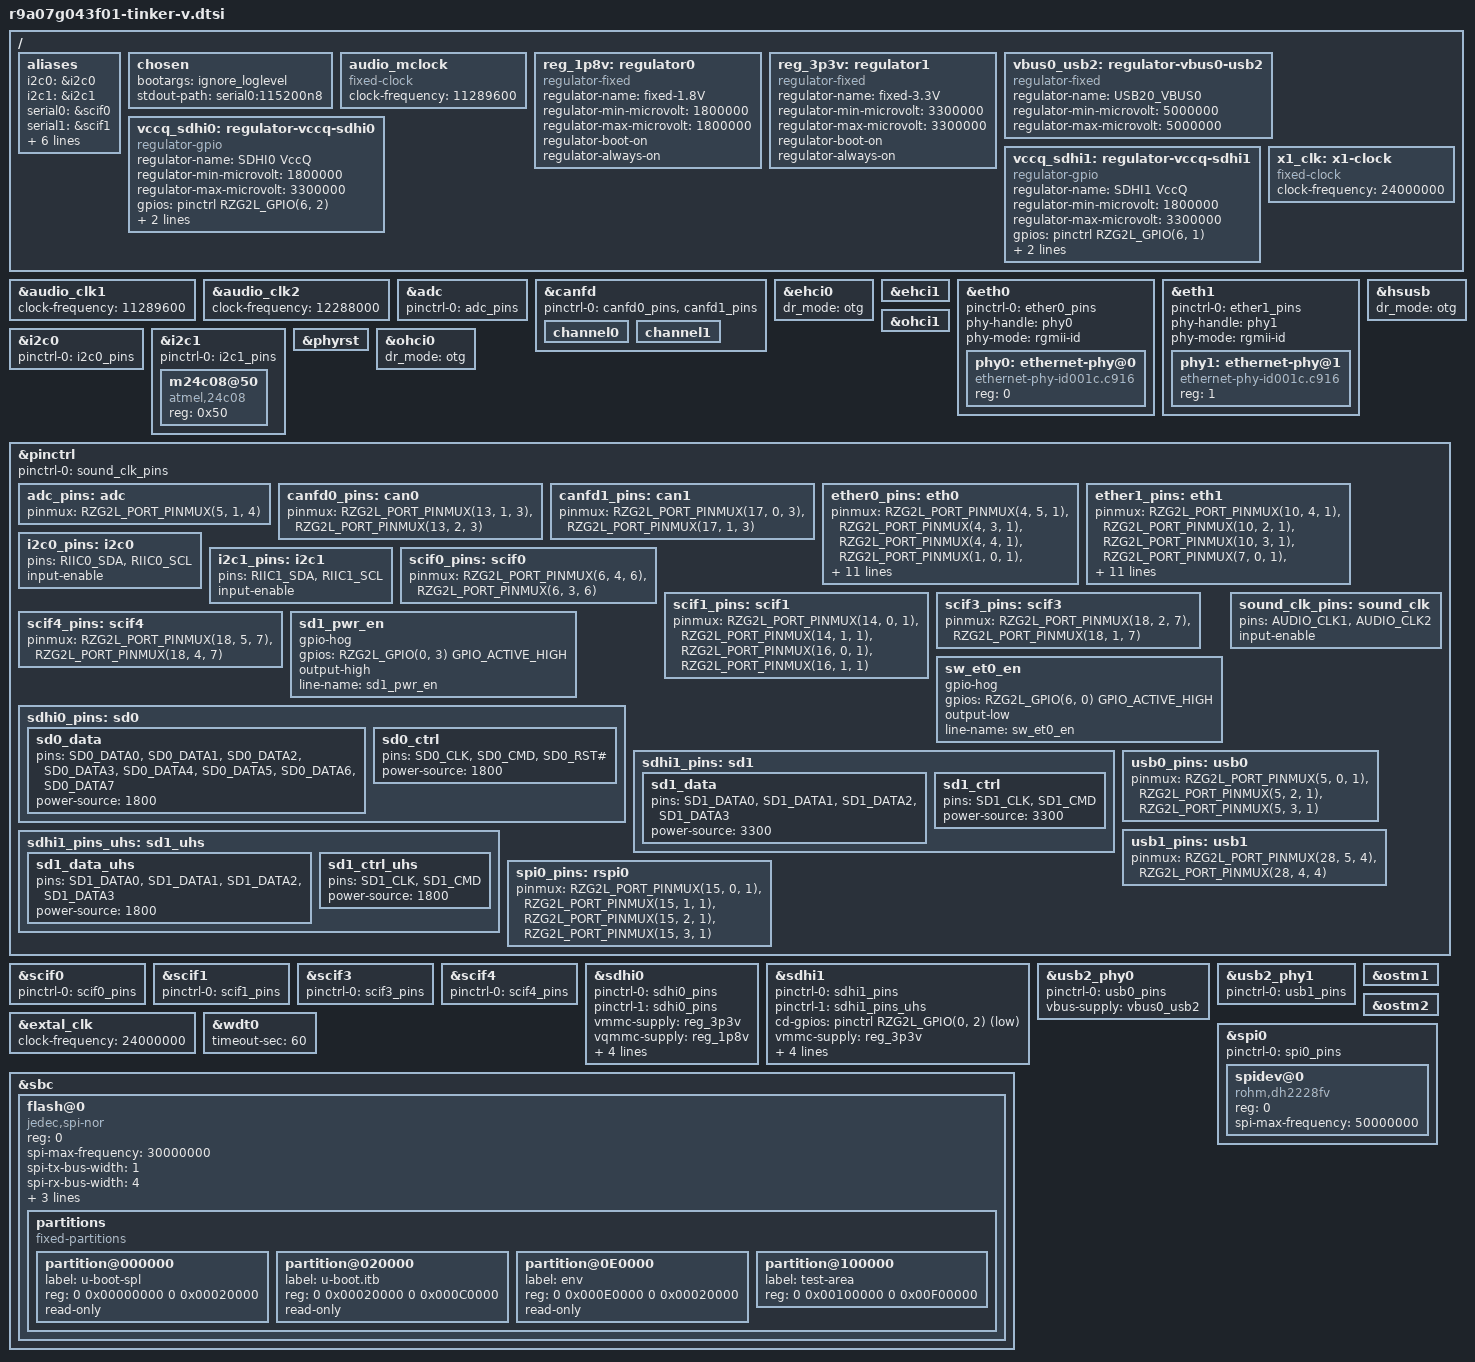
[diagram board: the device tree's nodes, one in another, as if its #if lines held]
// SPDX-License-Identifier: GPL-2.0
/*
 * Device Tree Source for the RZ/Five Evaluation Board Kit
 *
 * Copyright (C) 2022 Renesas Electronics Corp.
 */

#include <dt-bindings/pinctrl/rzg2l-pinctrl.h>
#include <dt-bindings/gpio/gpio.h>

/ {
	aliases {
		i2c0 = &i2c0;
		i2c1 = &i2c1;
		serial0 = &scif0;
		serial1 = &scif1;
		serial3 = &scif3;
		serial4 = &scif4;
		mmc0 = &sdhi0;
		mmc1 = &sdhi1;
		ethernet0 = &eth0;
		ethernet1 = &eth1;
	};

	chosen {
		bootargs = "ignore_loglevel";
		stdout-path = "serial0:115200n8";
	};

	audio_mclock: audio_mclock {
		compatible = "fixed-clock";
		#clock-cells = <0>;
		clock-frequency = <11289600>;
	};

	reg_1p8v: regulator0 {
		compatible = "regulator-fixed";

		regulator-name = "fixed-1.8V";
		regulator-min-microvolt = <1800000>;
		regulator-max-microvolt = <1800000>;
		regulator-boot-on;
		regulator-always-on;
	};

	reg_3p3v: regulator1 {
		compatible = "regulator-fixed";

		regulator-name = "fixed-3.3V";
		regulator-min-microvolt = <3300000>;
		regulator-max-microvolt = <3300000>;
		regulator-boot-on;
		regulator-always-on;
	};

	vbus0_usb2: regulator-vbus0-usb2 {
		compatible = "regulator-fixed";

		regulator-name = "USB20_VBUS0";
		regulator-min-microvolt = <5000000>;
		regulator-max-microvolt = <5000000>;
	};

#if !(SW_SW0_DEV_SEL)
	vccq_sdhi0: regulator-vccq-sdhi0 {
		compatible = "regulator-gpio";

		regulator-name = "SDHI0 VccQ";
		regulator-min-microvolt = <1800000>;
		regulator-max-microvolt = <3300000>;

		gpios = <&pinctrl RZG2L_GPIO(6, 2) GPIO_ACTIVE_HIGH>;

		gpios-states = <1>;
		states = <3300000 1
			  1800000 0>;
	};
#endif

	vccq_sdhi1: regulator-vccq-sdhi1 {
		compatible = "regulator-gpio";

		regulator-name = "SDHI1 VccQ";
		regulator-min-microvolt = <1800000>;
		regulator-max-microvolt = <3300000>;

		gpios = <&pinctrl RZG2L_GPIO(6, 1) GPIO_ACTIVE_HIGH>;

		gpios-states = <1>;
		states = <3300000 1
			  1800000 0>;
	};

	x1_clk: x1-clock {
		compatible = "fixed-clock";
		#clock-cells = <0>;
		clock-frequency = <24000000>;
	};
};

&audio_clk1{
	clock-frequency = <11289600>;
};

&audio_clk2{
	clock-frequency = <12288000>;
};

&adc {
	pinctrl-0 = <&adc_pins>;
	pinctrl-names = "default";
	status = "okay";
};

&canfd {
	pinctrl-0 = <&canfd0_pins &canfd1_pins>;
	pinctrl-names = "default";
	status = "okay";
	channel0 {
		status = "okay";
	};
	channel1 {
		status = "okay";
	};
};

&ehci0 {
	dr_mode = "otg";
	status = "okay";
};

&ehci1 {
	status = "okay";
};

&eth0 {
	pinctrl-0 = <&ether0_pins>;
	pinctrl-names = "default";
	phy-handle = <&phy0>;
	phy-mode = "rgmii-id";
	status = "okay";

	phy0: ethernet-phy@0 {
		compatible = "ethernet-phy-id001c.c916",
			     "ethernet-phy-ieee802.3-c22";
		reg = <0>;
	};
};

&eth1 {
	pinctrl-0 = <&ether1_pins>;
	pinctrl-names = "default";
	phy-handle = <&phy1>;
	phy-mode = "rgmii-id";
	status = "okay";

	phy1: ethernet-phy@1 {
		compatible = "ethernet-phy-id001c.c916",
			     "ethernet-phy-ieee802.3-c22";
		reg = <1>;
	};
};

&hsusb {
	dr_mode = "otg";
	status = "okay";
};

&i2c0 {
	pinctrl-0 = <&i2c0_pins>;
	pinctrl-names = "default";

	status = "okay";
};

&i2c1 {
	pinctrl-0 = <&i2c1_pins>;
	pinctrl-names = "default";
	status = "okay";

	m24c08@50 {
		compatible = "atmel,24c08";
		reg = <0x50>;
		status = "okay";
	};
};

&phyrst {
	status = "okay";
};

&ohci0 {
	dr_mode = "otg";
	status = "okay";
};

&ohci1 {
	status = "okay";
};

&pinctrl {
	pinctrl-0 = <&sound_clk_pins>;
	pinctrl-names = "default";

	adc_pins: adc {
		pinmux = <RZG2L_PORT_PINMUX(5, 1, 4)>; /* ADC_TRG */
	};

	canfd0_pins: can0 {
		pinmux = <RZG2L_PORT_PINMUX(13, 1, 3)>, /* TX */
			 <RZG2L_PORT_PINMUX(13, 2, 3)>; /* RX */
	};

	canfd1_pins: can1 {
		pinmux = <RZG2L_PORT_PINMUX(17, 0, 3)>, /* TX */
			 <RZG2L_PORT_PINMUX(17, 1, 3)>; /* RX */
	};

	ether0_pins: eth0 {
		pinmux = <RZG2L_PORT_PINMUX(4, 5, 1)>, /* ET0_LINKSTA */
			 <RZG2L_PORT_PINMUX(4, 3, 1)>, /* ET0_MDC */
			 <RZG2L_PORT_PINMUX(4, 4, 1)>, /* ET0_MDIO */
			 <RZG2L_PORT_PINMUX(1, 0, 1)>, /* ET0_TXC */
			 <RZG2L_PORT_PINMUX(1, 1, 1)>, /* ET0_TX_CTL */
			 <RZG2L_PORT_PINMUX(1, 2, 1)>, /* ET0_TXD0 */
			 <RZG2L_PORT_PINMUX(1, 3, 1)>, /* ET0_TXD1 */
			 <RZG2L_PORT_PINMUX(1, 4, 1)>, /* ET0_TXD2 */
			 <RZG2L_PORT_PINMUX(2, 0, 1)>, /* ET0_TXD3 */
			 <RZG2L_PORT_PINMUX(3, 0, 1)>, /* ET0_RXC */
			 <RZG2L_PORT_PINMUX(3, 1, 1)>, /* ET0_RX_CTL */
			 <RZG2L_PORT_PINMUX(3, 2, 1)>, /* ET0_RXD0 */
			 <RZG2L_PORT_PINMUX(3, 3, 1)>, /* ET0_RXD1 */
			 <RZG2L_PORT_PINMUX(4, 0, 1)>, /* ET0_RXD2 */
			 <RZG2L_PORT_PINMUX(4, 1, 1)>; /* ET0_RXD3 */
	};

	ether1_pins: eth1 {
		pinmux = <RZG2L_PORT_PINMUX(10, 4, 1)>, /* ET1_LINKSTA */
			 <RZG2L_PORT_PINMUX(10, 2, 1)>, /* ET1_MDC */
			 <RZG2L_PORT_PINMUX(10, 3, 1)>, /* ET1_MDIO */
			 <RZG2L_PORT_PINMUX(7, 0, 1)>, /* ET1_TXC */
			 <RZG2L_PORT_PINMUX(7, 1, 1)>, /* ET1_TX_CTL */
			 <RZG2L_PORT_PINMUX(7, 2, 1)>, /* ET1_TXD0 */
			 <RZG2L_PORT_PINMUX(7, 3, 1)>, /* ET1_TXD1 */
			 <RZG2L_PORT_PINMUX(7, 4, 1)>, /* ET1_TXD2 */
			 <RZG2L_PORT_PINMUX(8, 0, 1)>, /* ET1_TXD3 */
			 <RZG2L_PORT_PINMUX(8, 4, 1)>, /* ET1_RXC */
			 <RZG2L_PORT_PINMUX(9, 0, 1)>, /* ET1_RX_CTL */
			 <RZG2L_PORT_PINMUX(9, 1, 1)>, /* ET1_RXD0 */
			 <RZG2L_PORT_PINMUX(9, 2, 1)>, /* ET1_RXD1 */
			 <RZG2L_PORT_PINMUX(9, 3, 1)>, /* ET1_RXD2 */
			 <RZG2L_PORT_PINMUX(10, 0, 1)>; /* ET1_RXD3 */
	};

	i2c0_pins: i2c0 {
		pins = "RIIC0_SDA", "RIIC0_SCL";
		input-enable;
	};

	i2c1_pins: i2c1 {
		pins = "RIIC1_SDA", "RIIC1_SCL";
		input-enable;
	};

	scif0_pins: scif0 {
		pinmux = <RZG2L_PORT_PINMUX(6, 4, 6)>, /* TX */
			 <RZG2L_PORT_PINMUX(6, 3, 6)>; /* RX */
	};

	scif1_pins: scif1 {
		pinmux = <RZG2L_PORT_PINMUX(14, 0, 1)>, /* TX */
			 <RZG2L_PORT_PINMUX(14, 1, 1)>, /* RX */
			 <RZG2L_PORT_PINMUX(16, 0, 1)>, /* CTS */
			 <RZG2L_PORT_PINMUX(16, 1, 1)>; /* RTS */
	};

	scif3_pins: scif3 {
		pinmux = <RZG2L_PORT_PINMUX(18, 2, 7)>, /* TX */
			 <RZG2L_PORT_PINMUX(18, 1, 7)>; /* RX */
	};

	scif4_pins: scif4 {
		pinmux = <RZG2L_PORT_PINMUX(18, 5, 7)>, /* TX */
			 <RZG2L_PORT_PINMUX(18, 4, 7)>; /* RX */
	};

	sd1_pwr_en {
		gpio-hog;
		gpios = <RZG2L_GPIO(0, 3) GPIO_ACTIVE_HIGH>;
		output-high;
		line-name = "sd1_pwr_en";
	};

	sw_et0_en {
		gpio-hog;
		gpios = <RZG2L_GPIO(6, 0) GPIO_ACTIVE_HIGH>;
		output-low;
		line-name = "sw_et0_en";
	};

#if (SW_SW0_DEV_SEL)
	/* Support pinctrl for MMC function of SDHI0*/
	sdhi0_pins: sd0 {
		sd0_data {
			pins =  "SD0_DATA0", "SD0_DATA1", "SD0_DATA2",
				"SD0_DATA3", "SD0_DATA4", "SD0_DATA5",
				"SD0_DATA6", "SD0_DATA7";
			power-source  = <1800>;
		};

		sd0_ctrl {
			pins = "SD0_CLK", "SD0_CMD", "SD0_RST#";
			power-source = <1800>;
		};
	};
#else
	/* Support pinctrl for SD function of SDHI0 */
	sdhi0_pins: sd0 {
		sd0_data {
			pins =  "SD0_DATA0", "SD0_DATA1", "SD0_DATA2",
				"SD0_DATA3";
			power-source  = <3300>;
		};

		sd0_ctrl {
			pins = "SD0_CLK", "SD0_CMD";
			power-source = <3300>;
		};
	};

	sdhi0_pins_uhs: sd0_uhs {
		sd0_data_uhs {
			pins =	"SD0_DATA0", "SD0_DATA1", "SD0_DATA2",
				"SD0_DATA3";
			power-source  = <1800>;
		};

		sd0_ctrl_uhs {
			pins = "SD0_CLK", "SD0_CMD";
			power-source  = <1800>;
		};
	};
#endif

	sdhi1_pins: sd1 {
		sd1_data {
			pins =	"SD1_DATA0", "SD1_DATA1", "SD1_DATA2", "SD1_DATA3";
			power-source  = <3300>;
		};

		sd1_ctrl {
			pins = "SD1_CLK", "SD1_CMD";
			power-source  = <3300>;
		};
	};

	sdhi1_pins_uhs: sd1_uhs {
		sd1_data_uhs {
			pins =	"SD1_DATA0", "SD1_DATA1", "SD1_DATA2", "SD1_DATA3";
			power-source  = <1800>;
		};

		sd1_ctrl_uhs {
			pins = "SD1_CLK", "SD1_CMD";
			power-source  = <1800>;
		};
	};

	sound_clk_pins: sound_clk {
		pins = "AUDIO_CLK1", "AUDIO_CLK2";
		input-enable;
	};

	usb0_pins: usb0 {
		pinmux = <RZG2L_PORT_PINMUX(5, 0, 1)>, /* VBUS */
			 <RZG2L_PORT_PINMUX(5, 2, 1)>, /* OVC */
			 <RZG2L_PORT_PINMUX(5, 3, 1)>; /* OTG_ID */
	};

	usb1_pins: usb1 {
		pinmux = <RZG2L_PORT_PINMUX(28, 5, 4)>, /* OVC */
			 <RZG2L_PORT_PINMUX(28, 4, 4)>; /* VBUS */
	};

	spi0_pins: rspi0 {
		pinmux = <RZG2L_PORT_PINMUX(15, 0, 1)>, /* CK */
			 <RZG2L_PORT_PINMUX(15, 1, 1)>, /* MOSI */
			 <RZG2L_PORT_PINMUX(15, 2, 1)>, /* MISO */
			 <RZG2L_PORT_PINMUX(15, 3, 1)>; /* SSL */
	};
};

&scif0 {
	pinctrl-0 = <&scif0_pins>;
	pinctrl-names = "default";
	status = "okay";
};

&scif1 {
	pinctrl-0 = <&scif1_pins>;
	pinctrl-names = "default";
	status = "okay";
};

&scif3 {
	pinctrl-0 = <&scif3_pins>;
	pinctrl-names = "default";
	status = "okay";
};

&scif4 {
	pinctrl-0 = <&scif4_pins>;
	pinctrl-names = "default";
	status = "okay";
};

#if (SW_SW0_DEV_SEL)
&sdhi0 {
	pinctrl-0 = <&sdhi0_pins>;
	pinctrl-1 = <&sdhi0_pins>;
	pinctrl-names = "default", "state_uhs";

	vmmc-supply = <&reg_3p3v>;
	vqmmc-supply = <&reg_1p8v>;
	bus-width = <8>;
	mmc-hs200-1_8v;
	non-removable;
	fixed-emmc-driver-type = <1>;
	status = "okay";
};
#else
&sdhi0 {
	pinctrl-0 = <&sdhi0_pins>;
	pinctrl-1 = <&sdhi0_pins_uhs>;
	pinctrl-names = "default", "state_uhs";
	cd-gpios = <&pinctrl RZG2L_GPIO(0, 0) GPIO_ACTIVE_LOW>;

	vmmc-supply = <&reg_3p3v>;
	vqmmc-supply = <&vccq_sdhi0>;

	bus-width = <4>;
	sd-uhs-sdr50;
	sd-uhs-sdr104;
	status = "okay";
};
#endif

&sdhi1 {
	pinctrl-0 = <&sdhi1_pins>;
	pinctrl-1 = <&sdhi1_pins_uhs>;
	pinctrl-names = "default", "state_uhs";
	cd-gpios = <&pinctrl RZG2L_GPIO(0, 2) GPIO_ACTIVE_LOW>;

	vmmc-supply = <&reg_3p3v>;
	vqmmc-supply = <&vccq_sdhi1>;

	bus-width = <4>;
	sd-uhs-sdr50;
	sd-uhs-sdr104;
	status = "okay";
};

&usb2_phy0 {
	pinctrl-0 = <&usb0_pins>;
	pinctrl-names = "default";

	vbus-supply = <&vbus0_usb2>;
	status = "okay";
};

&usb2_phy1 {
	pinctrl-0 = <&usb1_pins>;
	pinctrl-names = "default";

	status = "okay";
};

&extal_clk {
	clock-frequency = <24000000>;
};

&wdt0 {
	status = "okay";
	timeout-sec = <60>;
};

&sbc {
	status = "okay";

	flash@0 {
		compatible = "jedec,spi-nor";
		reg = <0>;
		spi-max-frequency = <30000000>;

		spi-tx-bus-width = <1>;
		spi-rx-bus-width = <4>;

		/* SPI Mode 3 */
		spi-cpol;
		spi-cpha;
		m25p,fast-read;

		partitions {
			compatible = "fixed-partitions";
			#address-cells = <2>;
			#size-cells = <2>;

			partition@000000 {
				label = "u-boot-spl";
				reg = <0 0x00000000 0 0x00020000>;
				read-only;
			};
			partition@020000 {
				label = "u-boot.itb";
				reg = <0 0x00020000 0 0x000C0000>;
				read-only;
			};
			partition@0E0000 {
				label = "env";
				reg = <0 0x000E0000 0 0x00020000>;
				read-only;
			};
			partition@100000 {
				label = "test-area";
				reg = <0 0x00100000 0 0x00F00000>;
			};
		};
	};
};

&ostm1 {
	status = "okay";
};

&ostm2 {
	status = "okay";
};

&spi0 {
	pinctrl-0 = <&spi0_pins>;
	pinctrl-names = "default";
	status = "okay";

	spidev@0 {
		compatible = "rohm,dh2228fv";
		reg = <0>;
		spi-max-frequency = <50000000>;
		status = "okay";
	};
};
